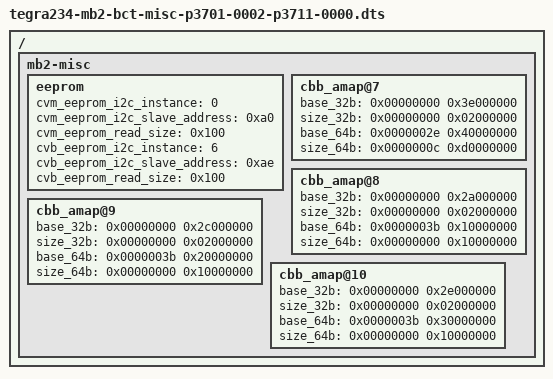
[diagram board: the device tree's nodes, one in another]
/dts-v1/;

#include "tegra234-mb2-bct-common.dtsi"
/ {
    mb2-misc {
        eeprom {
            cvm_eeprom_i2c_instance = <0>; //Starts from I2C bus 0
            cvm_eeprom_i2c_slave_address = <0xa0>; //0x50 << 1
            cvm_eeprom_read_size = <0x100>;
            cvb_eeprom_i2c_instance = <6>; //Starts from I2C bus 0
            cvb_eeprom_i2c_slave_address = <0xae>; //0x57 << 1
            cvb_eeprom_read_size = <0x100>;
        };
        cbb_amap@7 {
                base_32b = <0x00000000 0x3e000000>;
                size_32b = <0x00000000 0x02000000>;
                base_64b = <0x0000002e 0x40000000>;
                size_64b = <0x0000000c 0xd0000000>;
        };
        cbb_amap@8 {
                base_32b = <0x00000000 0x2a000000>;
                size_32b = <0x00000000 0x02000000>;
                base_64b = <0x0000003b 0x10000000>;
                size_64b = <0x00000000 0x10000000>;
        };
        cbb_amap@9 {
                base_32b = <0x00000000 0x2c000000>;
                size_32b = <0x00000000 0x02000000>;
                base_64b = <0x0000003b 0x20000000>;
                size_64b = <0x00000000 0x10000000>;
        };
        cbb_amap@10 {
                base_32b = <0x00000000 0x2e000000>;
                size_32b = <0x00000000 0x02000000>;
                base_64b = <0x0000003b 0x30000000>;
                size_64b = <0x00000000 0x10000000>;
        };
    };
};
